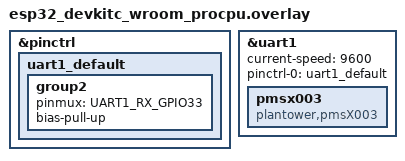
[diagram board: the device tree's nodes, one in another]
&pinctrl {
	uart1_default: uart1_default {
		group2 {
			pinmux = <UART1_RX_GPIO33>;
			bias-pull-up;
		};
	};
};

&uart1 {
	status = "okay";
	current-speed = <9600>;
	pinctrl-0 = <&uart1_default>;
	pmsx003: pmsx003 {
		compatible = "plantower,pmsX003";
		status = "okay";
	};
};
